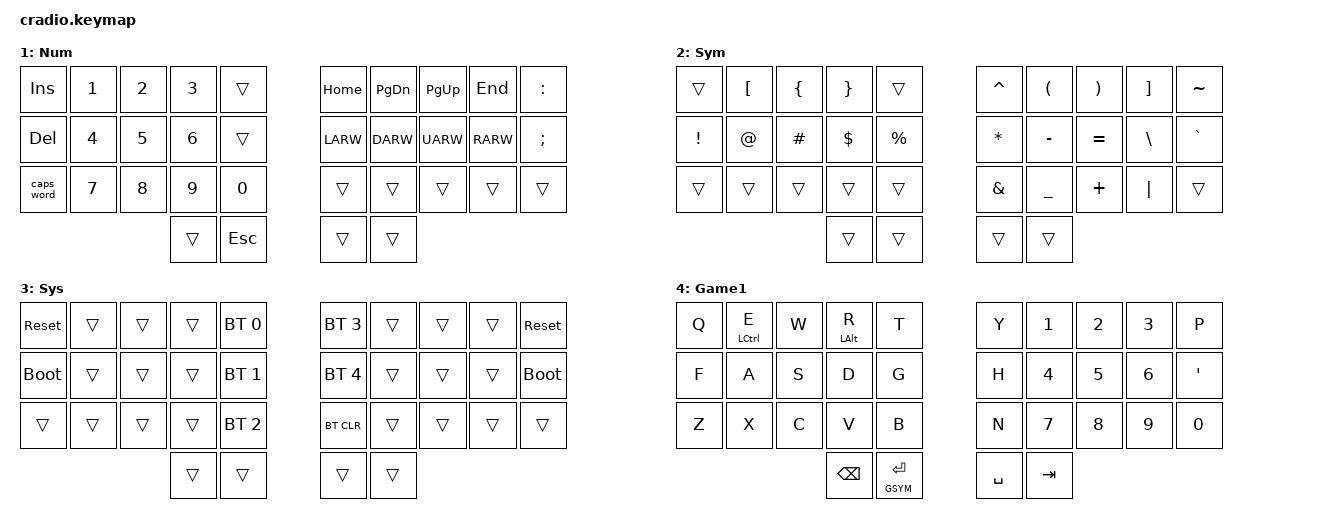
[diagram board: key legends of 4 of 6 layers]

#include <behaviors.dtsi>
#include <dt-bindings/zmk/keys.h>
#include <dt-bindings/zmk/bt.h>
#include <dt-bindings/zmk/outputs.h>

// Layer definitions
#define BASE 0
#define NUM 1
#define SYM 2
#define SYS 3
#define GAME 4
#define GSYM 5
// -----------------

// Home row mods macro
#define HRML(k1,k2,k3,k4) &ht LSHFT k1  &ht LALT k2  &ht LCTRL k3  &ht LGUI k4
#define HRMR(k1,k2,k3,k4) &ht RGUI k1  &ht RCTRL k2  &ht RALT k3  &ht RSHFT k4

&sk {
	// don't release mods on other mods presses
	ignore-modifiers;
};

/ {
	behaviors {
        ht: hold_tap {
            compatible = "zmk,behavior-hold-tap";
            #binding-cells = <2>;
            flavor = "tap-preferred";
            tapping-term-ms = <220>;
            quick-tap-ms = <150>;
            require-prior-idle-ms = <100>;
            bindings = <&kp>, <&kp>;
        };

		// Enables holding the first mod-tap key
		// by performing a tap-release-hold sequence.
		// To use it: "&qt KEYCODE1 KEYCODE2"
		qt: quick_tap {
			compatible = "zmk,behavior-hold-tap";
			label = "QUICK_TAP";
			#binding-cells = <2>;
			flavor = "hold-preferred";
			tapping-term-ms = <200>;
			quick-tap-ms = <200>;
			bindings = <&kp>, <&kp>;
		};
	};

	macros {
		// sometimes my device thinks a modifier is being held down
		// pressing all modifiers fixes it.
		unstick: unstick {
			label = "ZM_unstick";
			compatible = "zmk,behavior-macro";
			#binding-cells = <0>;
			bindings = <&kp LSHIFT &kp RSHIFT &kp LCTRL &kp RCTRL &kp LALT &kp RALT &kp LGUI &kp RGUI>;
		};
	};

    /* Potentially at other combos for more layers...
        combos {
            compatible = "zmk,combos";
            // both right thumb keys
            combo_accent {
                timeout-ms = <200>;
                key-positions = <32 33>;
                bindings = <&mo ACCENT>;
            };
            // internal-left & external-right thumb keys
            combo_sym2 {
                timeout-ms = <200>;
                key-positions = <31 33>;
                bindings = <&mo SYM2>;
            };
            // both left thumb keys
            combo_settings {
                timeout-ms = <200>;
                key-positions = <30 31>;
                bindings = <&mo SETTINGS>;
            };
            // left index & middle fingers (home-row)
            // hold control & space for Adobe workflow
            combo_ctrl_space {
                timeout-ms = <200>;
                key-positions = <12 13>;
                bindings = <&kp LC(SPACE)>;
                layers = <BASE>;
            };
        };
    */

    combos {
            compatible = "zmk,combos";
            // all thumb keys to toggle gaming layer
            combo_accent {
                timeout-ms = <200>;
                key-positions = <30 31 32 33>;
                bindings = <&tog GAME>;
            };
        };

    conditional_layers {
        compatible = "zmk,conditional-layers";
        tri_layer {
            if-layers = <NUM SYM>;
            then-layer = <SYS>;
        };
    };

	keymap {
		compatible = "zmk,keymap";

		// Base alpha layer
		default_layer {
			label = "Base";
			bindings = <
                //╭──────────┬──────────┬──────────┬──────────┬──────────╮   ╭──────────┬──────────┬──────────┬──────────┬──────────╮
                //│  Q       │  W       │  E       │  R       │  T       │   │  Y       │  U       │  I       │  O       │  P       │
                    &kp Q      &kp W      &kp E      &kp R      &kp T          &kp Y      &kp U      &kp I      &kp O      &kp P
                //├──────────┼──────────┼──────────┼──────────┼──────────┤   ├──────────┼──────────┼──────────┼──────────┼──────────┤
                //│  A       │  S       │  D       │  F       │  G       │   │  H       │  J       │  K       │  L       │ ' "      │
                   HRML(A,        S,         D,         F)       &kp G         &kp H    HRMR(J,         K,        L,         SQT) 
                //├──────────┼──────────┼──────────┼──────────┼──────────┤   ├──────────┼──────────┼──────────┼──────────┼──────────┤
                //│  Z       │  X       │  C       │  V       │  B       │   │  N       │  M       │ , <      │ . >      │ / ?      │
                    &kp Z      &kp X      &kp C      &kp V      &kp B          &kp N      &kp M      &kp COMMA  &kp DOT    &kp FSLH
                //╰──────────┴──────────┴──────────┼──────────┼──────────┤   ├──────────┼──────────┼──────────┴──────────┴──────────╯
                                                   &kp BSPC   &lt SYM ENTER  &lt NUM SPACE  &kp TAB
                //                                 ╰──────────┴──────────╯   ╰──────────┴──────────╯
            >;
		};

		// Numbers, arrows, some others... lol 
		num_layer {
			label = "Num";
			bindings = <
                //╭──────────┬──────────┬──────────┬──────────┬──────────╮   ╭──────────┬──────────┬──────────┬──────────┬──────────╮
                //│ INSERT   │  1       │  2       │  3       │          │   │ HOME     │ PAGE DN  │ PAGE UP  │ END      │  :       │
                    &kp INS    &kp N1     &kp N2     &kp N3     &trans         &kp HOME   &kp PG_DN  &kp PG_UP  &kp END    &kp COLON
                //├──────────┼──────────┼──────────┼──────────┼──────────┤   ├──────────┼──────────┼──────────┼──────────┼──────────┤
                //│ DELETE   │  4       │  5       │  6       │          │   │ LEFT     │ DOWN     │ UP       │ RIGHT    │  ;       │
                    &kp DEL    &kp N4     &kp N5     &kp N6     &trans         &kp LARW   &kp DARW   &kp UARW   &kp RARW   &kp SEMI
                //├──────────┼──────────┼──────────┼──────────┼──────────┤   ├──────────┼──────────┼──────────┼──────────┼──────────┤
                //│ CAPS     │  7       │  8       │  9       │  0       │   │          │          │          │          │          │
                   &caps_word  &kp N7     &kp N8     &kp N9     &kp N0         &trans     &trans     &trans     &trans     &trans
                //╰──────────┴──────────┴──────────┼──────────┼──────────┤   ├──────────┼──────────┼──────────┴──────────┴──────────╯
                                                     &trans     &kp ESC        &trans     &trans
                //                                 ╰──────────┴──────────╯   ╰──────────┴──────────╯
			>;
		};

		// Main modifiers and arrow keys
		sym_layer {
			label = "Sym";
			bindings = <
                //╭──────────┬──────────┬──────────┬──────────┬──────────╮   ╭──────────┬──────────┬──────────┬──────────┬──────────╮
                //│          │  [       │  {       │  }       │          │   │  ^       │  (       │  )       │  ]       │  ~       │
                    &trans     &kp LBKT   &kp LBRC   &kp RBRC   &trans         &kp CARET  &kp LPAR   &kp RPAR   &kp RBKT   &kp TILDE
                //├──────────┼──────────┼──────────┼──────────┼──────────┤   ├──────────┼──────────┼──────────┼──────────┼──────────┤
                //│  !       │  @       │  #       │  $       │  %       │   │  *       │  -       │  =       │  \       │  `       │
                    &kp EXCL   &kp AT     &kp HASH   &kp DLLR   &kp PRCNT      &kp ASTRK  &kp MINUS  &kp EQUAL  &kp BSLH   &kp GRAVE
                //├──────────┼──────────┼──────────┼──────────┼──────────┤   ├──────────┼──────────┼──────────┼──────────┼──────────┤
                //│          │          │          │          │          │   │  &       │  _       │  +       │  │       │          │
                    &trans     &trans     &trans     &trans     &trans         &kp AMPS   &kp UNDER  &kp PLUS   &kp PIPE   &trans
                //╰──────────┴──────────┴──────────┼──────────┼──────────┤   ├──────────┼──────────┼──────────┴──────────┴──────────╯
                                                     &trans     &trans         &trans     &trans
                //                                 ╰──────────┴──────────╯   ╰──────────┴──────────╯
			>;
		};

		// Used to change the keyboard's settings.
		system_layer {
            label = "Sys";
            bindings = <
                //╭──────────┬──────────┬──────────┬──────────┬──────────╮   ╭──────────┬──────────┬──────────┬──────────┬──────────╮
                //│ RESET    │          │          │          │PROFILE 0 │   │PROFILE 2 │          │          │          │  RESET   │
                   &sys_reset  &trans     &trans     &trans    &bt BT_SEL 0   &bt BT_SEL 3  &trans     &trans     &trans    &sys_reset
                //├──────────┼──────────┼──────────┼──────────┼──────────┤   ├──────────┼──────────┼──────────┼──────────┼──────────┤
                //│BOOTLOADER│          │          │          │PROFILE 1 │   │PROFILE 3 │          │          │          │BOOTLOADER│
                  &bootloader  &trans     &trans     &trans    &bt BT_SEL 1   &bt BT_SEL 4  &trans     &trans     &trans    &bootloader
                //├──────────┼──────────┼──────────┼──────────┼──────────┤   ├──────────┼──────────┼──────────┼──────────┼──────────┤
                //│          │          │          │          │PROFILE 2 │   │ CLEAR BT │          │          │          │          │
                    &trans     &trans     &trans    &trans     &bt BT_SEL 2   &bt BT_CLR  &trans     &trans     &trans     &trans
                //╰──────────┴──────────┴──────────┼──────────┼──────────┤   ├──────────┼──────────┼──────────┴──────────┴──────────╯
                                                     &trans     &trans         &trans     &trans
                //                                 ╰──────────┴──────────╯   ╰──────────┴──────────╯
			>;
		};

        gaming_layer {
            label = "Game1";
            bindings = <
                //╭──────────┬──────────┬──────────┬──────────┬──────────╮   ╭──────────┬──────────┬──────────┬──────────┬──────────╮
                //│  Q       │  E       │  W       │  R       │  T       │   │  Y       │  1       │  2       │  3       │  P       │
                     &kp Q    &ht LCTRL E  &kp W    &ht LALT R   &kp T          &kp Y      &kp N1     &kp N2     &kp N3     &kp P
                //├──────────┼──────────┼──────────┼──────────┼──────────┤   ├──────────┼──────────┼──────────┼──────────┼──────────┤
                //│  F       │  A       │  S       │  D       │  G       │   │  H       │  4       │  5       │  6       │ ' "      │
                     &kp F      &kp A      &kp S      &kp  D     &kp G          &kp H      &kp N4     &kp N5     &kp N6    &kp SQT
                //├──────────┼──────────┼──────────┼──────────┼──────────┤   ├──────────┼──────────┼──────────┼──────────┼──────────┤
                //│  Z       │  X       │  C       │  V       │  B       │   │  N       │  7       │ 8        │ 9        │ 0        │
                     &kp Z      &kp X      &kp C      &kp V      &kp B          &kp N      &kp N7    &kp N8     &kp N9     &kp N0
                //╰──────────┴──────────┴──────────┼──────────┼──────────┤   ├──────────┼──────────┼──────────┴──────────┴──────────╯
                                                   &kp BSPC   &lt GSYM ENTER   &kp SPACE   &kp TAB
                //                                 ╰──────────┴──────────╯   ╰──────────┴──────────╯

			>;
		};

        gaming_sym_layer {
            label = "Game2";
            bindings = <
                //╭──────────┬──────────┬──────────┬──────────┬──────────╮   ╭──────────┬──────────┬──────────┬──────────┬──────────╮
                //│          │          │          │          │          │   │  Y       │  U       │  I       │  O       │  P       │
                     &trans     &trans      &trans     &trans     &trans          &kp Y      &kp U      &kp I      &kp O      &kp P
                //├──────────┼──────────┼──────────┼──────────┼──────────┤   ├──────────┼──────────┼──────────┼──────────┼──────────┤
                //│          │          │          │          │          │   │  H       │  J       │  K       │  L       │ ' "      │
                     &trans     &trans      &trans     &trans     &trans          &kp H    HRMR(J,   K,        L,        SQT)
                //├──────────┼──────────┼──────────┼──────────┼──────────┤   ├──────────┼──────────┼──────────┼──────────┼──────────┤
                //│          │          │          │          │          │   │  N       │  M       │ , <      │ . >      │ / ?      │
                     &trans     &trans      &trans     &trans     &trans        &kp N      &kp M     &kp COMMA  &kp DOT    &kp FSLH
                //╰──────────┴──────────┴──────────┼──────────┼──────────┤   ├──────────┼──────────┼──────────┴──────────┴──────────╯
                                                     &trans     &trans          &kp ESC    &trans  
                //                                 ╰──────────┴──────────╯   ╰──────────┴──────────╯

			>;
		};
	};
};
